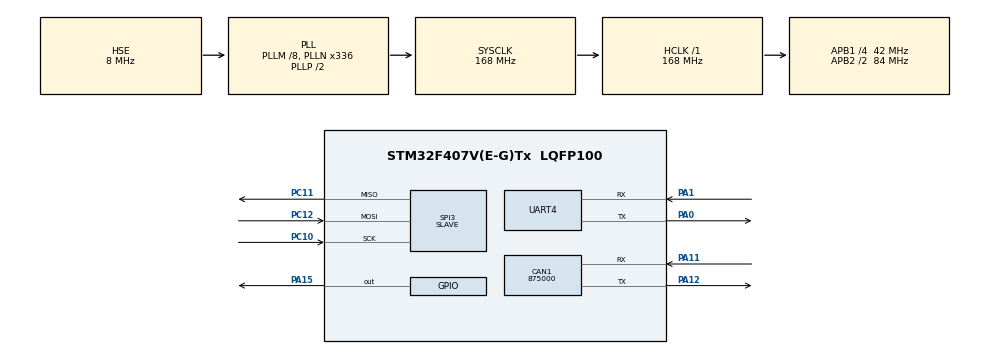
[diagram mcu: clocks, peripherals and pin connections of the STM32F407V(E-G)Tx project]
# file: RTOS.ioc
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ADC1.Channel-0\#ChannelRegularConversion=ADC_CHANNEL_TEMPSENSOR
ADC1.NbrOfConversionFlag=1
ADC1.Rank-0\#ChannelRegularConversion=1
ADC1.SamplingTime-0\#ChannelRegularConversion=ADC_SAMPLETIME_3CYCLES
ADC1.master=1
CAN1.CalculateBaudRate=875000
CAN1.CalculateTimeBit=1142
CAN1.CalculateTimeQuantum=380.95238095238096
FREERTOS.Tasks01=defaultTask,0,128,StartDefaultTask,Default,NULL,Dynamic,NULL,NULL;SensorTask,0,128,SensorTask1,Default,NULL,Dynamic,NULL,NULL;TempTask,0,128,TempTask1,Default,NULL,Dynamic,NULL,NULL;CommsTask,0,128,CommsTask1,Default,NULL,Dynamic,NULL,NULL;ErrorMonitorTas,0,128,ErrorMonitorTask1,Default,NULL,Dynamic,NULL,NULL
Mcu.Family=STM32F4
Mcu.Name=STM32F407V(E-G)Tx
Mcu.Package=LQFP100
NVIC.PriorityGroup=NVIC_PRIORITYGROUP_4
NVIC.SPI3_IRQn=true\:5\:0\:false\:false\:true\:true\:true\:true\:true
NVIC.TIM3_IRQn=true\:0\:0\:false\:false\:true\:false\:false\:true\:true
NVIC.TimeBase=TIM3_IRQn
NVIC.TimeBaseIP=TIM3
PA0-WKUP.Mode=Asynchronous
PA0-WKUP.Signal=UART4_TX
PA1.Mode=Asynchronous
PA1.Signal=UART4_RX
PA11.Mode=CAN_Activate
PA11.Signal=CAN1_RX
PA12.Mode=CAN_Activate
PA12.Signal=CAN1_TX
PA15.Signal=GPIO_Output
PC10.Mode=Full_Duplex_Slave
PC10.Signal=SPI3_SCK
PC11.Mode=Full_Duplex_Slave
PC11.Signal=SPI3_MISO
PC12.Mode=Full_Duplex_Slave
PC12.Signal=SPI3_MOSI
ProjectManager.HeapSize=0x200
ProjectManager.StackSize=0x400
ProjectManager.TargetToolchain=STM32CubeIDE
RCC.48MHZClocksFreq_Value=48000000
RCC.AHBFreq_Value=168000000
RCC.APB1CLKDivider=RCC_HCLK_DIV4
RCC.APB1Freq_Value=42000000
RCC.APB1TimFreq_Value=84000000
RCC.APB2CLKDivider=RCC_HCLK_DIV2
RCC.APB2Freq_Value=84000000
RCC.APB2TimFreq_Value=168000000
RCC.CortexFreq_Value=168000000
RCC.HCLKFreq_Value=168000000
RCC.HSE_VALUE=8000000
RCC.HSI_VALUE=16000000
RCC.LSE_VALUE=32768
RCC.PLLM=8
RCC.PLLN=336
RCC.PLLQ=7
RCC.PLLSourceVirtual=RCC_PLLSOURCE_HSE
RCC.SYSCLKFreq_VALUE=168000000
RCC.SYSCLKSource=RCC_SYSCLKSOURCE_PLLCLK
RCC.VCOOutputFreq_Value=336000000
SPI3.Direction=SPI_DIRECTION_2LINES
SPI3.Mode=SPI_MODE_SLAVE
SPI3.VirtualType=VM_SLAVE
UART4.VirtualMode=Asynchronous
VP_ADC1_TempSens_Input.Mode=IN-TempSens
VP_FREERTOS_VS_CMSIS_V1.Mode=CMSIS_V1
VP_SYS_VS_tim3.Mode=TIM3
board=STM32F407G-DISC1

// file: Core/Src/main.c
/* USER CODE BEGIN Header */
/**
  ******************************************************************************
  * @file           : main.c
  * @brief          : Main program body
  ******************************************************************************
  * @attention
  *
  * Copyright (c) 2025 STMicroelectronics.
  * All rights reserved.
  *
  * This software is licensed under terms that can be found in the LICENSE file
  * in the root directory of this software component.
  * If no LICENSE file comes with this software, it is provided AS-IS.
  *
  ******************************************************************************
  */
/* USER CODE END Header */
#include "main.h"
#include "cmsis_os.h"

/* USER CODE BEGIN Includes */
#include <string.h>  // memset, memcpy için
#include <stdio.h>
#include "SensorTask.h"
#include "CommsTask.h"
#include "TempTask.h"
#include "ErrorMonitorTask.h"

/* USER CODE END Includes */

ADC_HandleTypeDef hadc1;

CAN_HandleTypeDef hcan1;

SPI_HandleTypeDef hspi3;

UART_HandleTypeDef huart4;

osThreadId defaultTaskHandle;
osThreadId SensorTaskHandle;
osThreadId TempTaskHandle;
osThreadId CommsTaskHandle;
osThreadId ErrorMonitorTasHandle;

void SystemClock_Config(void);
static void MX_GPIO_Init(void);
static void MX_CAN1_Init(void);
static void MX_UART4_Init(void);
static void MX_ADC1_Init(void);
static void MX_SPI3_Init(void);
void StartDefaultTask(void const * argument);
void SensorTask1(void const * argument);
void TempTask1(void const * argument);
void CommsTask1(void const * argument);
void ErrorMonitorTask1(void const * argument);

/* USER CODE BEGIN 0 */

//IMUDAN VERİ OKUMAMIZ İÇİN KULLANILAN DEĞİŞKENLER
IMU_Data_t imu_data;

///////////////////////////////////////////

//Sistem zamanı için değişken
uint16_t previous_tick = 0;
uint16_t systick_counter = 0;
////////////////////////
/* USER CODE END 0 */

int main(void)
{

  /* MCU Configuration--------------------------------------------------------*/

  /* Reset of all peripherals, Initializes the Flash interface and the Systick. */
  HAL_Init();

  /* Configure the system clock */
  SystemClock_Config();

  /* Initialize all configured peripherals */
  MX_GPIO_Init();
  MX_CAN1_Init();
  MX_UART4_Init();
  MX_ADC1_Init();
  MX_SPI3_Init();

  /* Create the thread(s) */
  /* definition and creation of defaultTask */
  osThreadDef(defaultTask, StartDefaultTask, osPriorityNormal, 0, 128);
  defaultTaskHandle = osThreadCreate(osThread(defaultTask), NULL);

  /* definition and creation of SensorTask */
  osThreadDef(SensorTask, SensorTask1, osPriorityNormal, 0, 128);
  SensorTaskHandle = osThreadCreate(osThread(SensorTask), NULL);

  /* definition and creation of TempTask */
  osThreadDef(TempTask, TempTask1, osPriorityNormal, 0, 128);
  TempTaskHandle = osThreadCreate(osThread(TempTask), NULL);

  /* definition and creation of CommsTask */
  osThreadDef(CommsTask, CommsTask1, osPriorityNormal, 0, 128);
  CommsTaskHandle = osThreadCreate(osThread(CommsTask), NULL);

  /* definition and creation of ErrorMonitorTas */
  osThreadDef(ErrorMonitorTas, ErrorMonitorTask1, osPriorityNormal, 0, 128);
  ErrorMonitorTasHandle = osThreadCreate(osThread(ErrorMonitorTas), NULL);

  /* Start scheduler */
  osKernelStart();

  /* We should never get here as control is now taken by the scheduler */

  /* Infinite loop */
  while (1)
  {
	  if ((HAL_GetTick() - previous_tick) >= 1000)  // 1000 ms = 1 saniye
	  	          {
	  	              previous_tick = HAL_GetTick();  // zamanı güncelle
	  	              systick_counter++;              // her saniyede bir artar
	  	              imu_data.timestamp = systick_counter;
	  	          }
  }
}

void SystemClock_Config(void)
{
  RCC_OscInitTypeDef RCC_OscInitStruct = {0};
  RCC_ClkInitTypeDef RCC_ClkInitStruct = {0};

  /** Configure the main internal regulator output voltage
  */
  __HAL_RCC_PWR_CLK_ENABLE();
  __HAL_PWR_VOLTAGESCALING_CONFIG(PWR_REGULATOR_VOLTAGE_SCALE1);

  /** Initializes the RCC Oscillators according to the specified parameters
  * in the RCC_OscInitTypeDef structure.
  */
  RCC_OscInitStruct.OscillatorType = RCC_OSCILLATORTYPE_HSE;
  RCC_OscInitStruct.HSEState = RCC_HSE_OFF;
  RCC_OscInitStruct.PLL.PLLState = RCC_PLL_ON;
  RCC_OscInitStruct.PLL.PLLSource = RCC_PLLSOURCE_HSE;
  RCC_OscInitStruct.PLL.PLLM = 8;
  RCC_OscInitStruct.PLL.PLLN = 336;
  RCC_OscInitStruct.PLL.PLLP = RCC_PLLP_DIV2;
  RCC_OscInitStruct.PLL.PLLQ = 7;
  if (HAL_RCC_OscConfig(&RCC_OscInitStruct) != HAL_OK)
  {
    Error_Handler();
  }

  /** Initializes the CPU, AHB and APB buses clocks
  */
  RCC_ClkInitStruct.ClockType = RCC_CLOCKTYPE_HCLK|RCC_CLOCKTYPE_SYSCLK
                              |RCC_CLOCKTYPE_PCLK1|RCC_CLOCKTYPE_PCLK2;
  RCC_ClkInitStruct.SYSCLKSource = RCC_SYSCLKSOURCE_PLLCLK;
  RCC_ClkInitStruct.AHBCLKDivider = RCC_SYSCLK_DIV1;
  RCC_ClkInitStruct.APB1CLKDivider = RCC_HCLK_DIV4;
  RCC_ClkInitStruct.APB2CLKDivider = RCC_HCLK_DIV2;

  if (HAL_RCC_ClockConfig(&RCC_ClkInitStruct, FLASH_LATENCY_5) != HAL_OK)
  {
    Error_Handler();
  }
}

static void MX_ADC1_Init(void)
{

  ADC_ChannelConfTypeDef sConfig = {0};

  /** Configure the global features of the ADC (Clock, Resolution, Data Alignment and number of conversion)
  */
  hadc1.Instance = ADC1;
  hadc1.Init.ClockPrescaler = ADC_CLOCK_SYNC_PCLK_DIV4;
  hadc1.Init.Resolution = ADC_RESOLUTION_12B;
  hadc1.Init.ScanConvMode = DISABLE;
  hadc1.Init.ContinuousConvMode = DISABLE;
  hadc1.Init.DiscontinuousConvMode = DISABLE;
  hadc1.Init.ExternalTrigConvEdge = ADC_EXTERNALTRIGCONVEDGE_NONE;
  hadc1.Init.ExternalTrigConv = ADC_SOFTWARE_START;
  hadc1.Init.DataAlign = ADC_DATAALIGN_RIGHT;
  hadc1.Init.NbrOfConversion = 1;
  hadc1.Init.DMAContinuousRequests = DISABLE;
  hadc1.Init.EOCSelection = ADC_EOC_SINGLE_CONV;
  if (HAL_ADC_Init(&hadc1) != HAL_OK)
  {
    Error_Handler();
  }

  /** Configure for the selected ADC regular channel its corresponding rank in the sequencer and its sample time.
  */
  sConfig.Channel = ADC_CHANNEL_TEMPSENSOR;
  sConfig.Rank = 1;
  sConfig.SamplingTime = ADC_SAMPLETIME_3CYCLES;
  if (HAL_ADC_ConfigChannel(&hadc1, &sConfig) != HAL_OK)
  {
    Error_Handler();
  }

}

static void MX_CAN1_Init(void)
{

  hcan1.Instance = CAN1;
  hcan1.Init.Prescaler = 16;
  hcan1.Init.Mode = CAN_MODE_NORMAL;
  hcan1.Init.SyncJumpWidth = CAN_SJW_1TQ;
  hcan1.Init.TimeSeg1 = CAN_BS1_1TQ;
  hcan1.Init.TimeSeg2 = CAN_BS2_1TQ;
  hcan1.Init.TimeTriggeredMode = DISABLE;
  hcan1.Init.AutoBusOff = DISABLE;
  hcan1.Init.AutoWakeUp = DISABLE;
  hcan1.Init.AutoRetransmission = DISABLE;
  hcan1.Init.ReceiveFifoLocked = DISABLE;
  hcan1.Init.TransmitFifoPriority = DISABLE;
  if (HAL_CAN_Init(&hcan1) != HAL_OK)
  {
    Error_Handler();
  }

}

static void MX_SPI3_Init(void)
{

  /* SPI3 parameter configuration*/
  hspi3.Instance = SPI3;
  hspi3.Init.Mode = SPI_MODE_SLAVE;
  hspi3.Init.Direction = SPI_DIRECTION_2LINES;
  hspi3.Init.DataSize = SPI_DATASIZE_8BIT;
  hspi3.Init.CLKPolarity = SPI_POLARITY_LOW;
  hspi3.Init.CLKPhase = SPI_PHASE_1EDGE;
  hspi3.Init.NSS = SPI_NSS_SOFT;
  hspi3.Init.FirstBit = SPI_FIRSTBIT_MSB;
  hspi3.Init.TIMode = SPI_TIMODE_DISABLE;
  hspi3.Init.CRCCalculation = SPI_CRCCALCULATION_DISABLE;
  hspi3.Init.CRCPolynomial = 10;
  if (HAL_SPI_Init(&hspi3) != HAL_OK)
  {
    Error_Handler();
  }

}

static void MX_UART4_Init(void)
{

  huart4.Instance = UART4;
  huart4.Init.BaudRate = 115200;
  huart4.Init.WordLength = UART_WORDLENGTH_8B;
  huart4.Init.StopBits = UART_STOPBITS_1;
  huart4.Init.Parity = UART_PARITY_NONE;
  huart4.Init.Mode = UART_MODE_TX_RX;
  huart4.Init.HwFlowCtl = UART_HWCONTROL_NONE;
  huart4.Init.OverSampling = UART_OVERSAMPLING_16;
  if (HAL_UART_Init(&huart4) != HAL_OK)
  {
    Error_Handler();
  }

}

static void MX_GPIO_Init(void)
{
  GPIO_InitTypeDef GPIO_InitStruct = {0};

  /* GPIO Ports Clock Enable */
  __HAL_RCC_GPIOA_CLK_ENABLE();
  __HAL_RCC_GPIOC_CLK_ENABLE();

  /*Configure GPIO pin Output Level */
  HAL_GPIO_WritePin(GPIOA, GPIO_PIN_15, GPIO_PIN_RESET);

  /*Configure GPIO pin : PA15 */
  GPIO_InitStruct.Pin = GPIO_PIN_15;
  GPIO_InitStruct.Mode = GPIO_MODE_OUTPUT_PP;
  GPIO_InitStruct.Pull = GPIO_NOPULL;
  GPIO_InitStruct.Speed = GPIO_SPEED_FREQ_LOW;
  HAL_GPIO_Init(GPIOA, &GPIO_InitStruct);

}

void StartDefaultTask(void const * argument)
{
  for(;;)
  {
    osDelay(1);
  }
}

void HAL_TIM_PeriodElapsedCallback(TIM_HandleTypeDef *htim)
{
  if (htim->Instance == TIM3)
  {
    HAL_IncTick();
  }
}

void Error_Handler(void)
{
  __disable_irq();
  while (1)
  {
  }
}
